# MK51D7 register map
File version: 1.6
Registers are 32-bit, read-write, reset 0x0 unless marked. A register's access mark holds for its fields unless they carry their own. Offsets are from the block's base; [hi:lo] are bit positions; 'fields as' and 'values as' point back to an identical list.

## TRIAMP0 — Trans-Impedance Amplifier
Base 0x400F8000; register names take the prefix TRIAMP0_
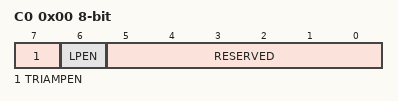
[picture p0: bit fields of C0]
0x00 C0 8-bit — Control Register 0
  [7] TRIAMPEN — TRIAMP Enable
    0=The amplifier is disabled and not powered; 1=TRIAMP system is enabled. In this mode the amplifier is powered and enabled.
  [6] LPEN — Low-Power Enable
    0=High-speed mode selected. In this mode, TRIAMP has faster slew rate and unity gain bandwidth performance with higher current consumption.; 1=Low-power mode selected. In this mode, TRIAMP has lower current consumption with slower slew rate and unity gain bandwidth performance.
  [5:0] RESERVED ro

## PTA — General Purpose Input/Output
Base 0x400FF000; register names take the prefix GPIOA_
0x00 PDOR — Port Data Output Register
  [31:0] PDO — Port Data Output
    0=Logic level 0 is driven on pin provided pin is configured for General Purpose Output; 1=Logic level 1 is driven on pin provided pin is configured for General Purpose Output
0x04 PSOR wo — Port Set Output Register
  [31:0] PTSO — Port Set Output
    0=Corresponding bit in PDORn does not change; 1=Corresponding bit in PDORn is set to logic one
0x08 PCOR wo — Port Clear Output Register
  [31:0] PTCO — Port Clear Output
    0=Corresponding bit in PDORn does not change; 1=Corresponding bit in PDORn is cleared to logic zero
0x0C PTOR wo — Port Toggle Output Register
  [31:0] PTTO — Port Toggle Output
    0=Corresponding bit in PDORn does not change; 1=Corresponding bit in PDORn is set to the inverse of its existing logic state
0x10 PDIR ro — Port Data Input Register
  [31:0] PDI — Port Data Input
    0=Pin logic level is logic zero or is configured for use by digital function; 1=Pin logic level is logic one
0x14 PDDR — Port Data Direction Register
  [31:0] PDD — Port data direction
    0=Pin is configured as general purpose input, if configured for the GPIO function; 1=Pin is configured for general purpose output, if configured for the GPIO function

## PTB — General Purpose Input/Output
Base 0x400FF040; register names take the prefix GPIOB_
Registers as PTA.

## PTC — General Purpose Input/Output
Base 0x400FF080; register names take the prefix GPIOC_
Registers as PTA; these are added or differ:
0x08 PCOR wo — Port Clear Output Register
  [31:0] PTCO — Port Clear Output
    0=Corresponding bit in PDORn does not change; 1=Corresponding bit in PDORn is cleared to logic zero

## PTD — General Purpose Input/Output
Base 0x400FF0C0; register names take the prefix GPIOD_
Registers as PTA.

## PTE — General Purpose Input/Output
Base 0x400FF100; register names take the prefix GPIOE_
Registers as PTA.

## MCM — Core Platform Miscellaneous Control Module
Base 0xE0080000; register names take the prefix MCM_
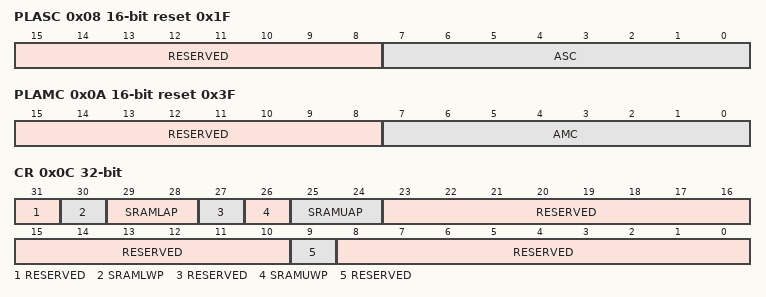
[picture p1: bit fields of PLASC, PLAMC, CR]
0x08 PLASC 16-bit ro reset 0x1F — Crossbar switch (AXBS) slave configuration
  [15:8] RESERVED
  [7:0] ASC — Each bit in the ASC field indicates if there is a corresponding connection to the crossbar switch's slave input port.
    0=A bus slave connection to AXBS input port n is absent; 1=A bus slave connection to AXBS input port n is present
0x0A PLAMC 16-bit ro reset 0x3F — Crossbar switch (AXBS) master configuration
  [15:8] RESERVED
  [7:0] AMC — Each bit in the AMC field indicates if there is a corresponding connection to the AXBS master input port.
    0=A bus master connection to AXBS input port n is absent; 1=A bus master connection to AXBS input port n is present
0x0C CR — Control register
  [31] RESERVED ro
  [30] SRAMLWP — SRAM_L write protect
  [29:28] SRAMLAP — SRAM_L arbitration priority
    0=Round robin; 1=Special round robin (favors SRAM backoor accesses over the processor); 2=Fixed priority. Processor has highest, backdoor has lowest; 3=Fixed priority. Backdoor has highest, processor has lowest
  [27] RESERVED ro
  [26] SRAMUWP — SRAM_U write protect
  [25:24] SRAMUAP — SRAM_U arbitration priority
    values as SRAMLAP
  [23:10] RESERVED ro
  [9] RESERVED ro
  [8:0] RESERVED ro
